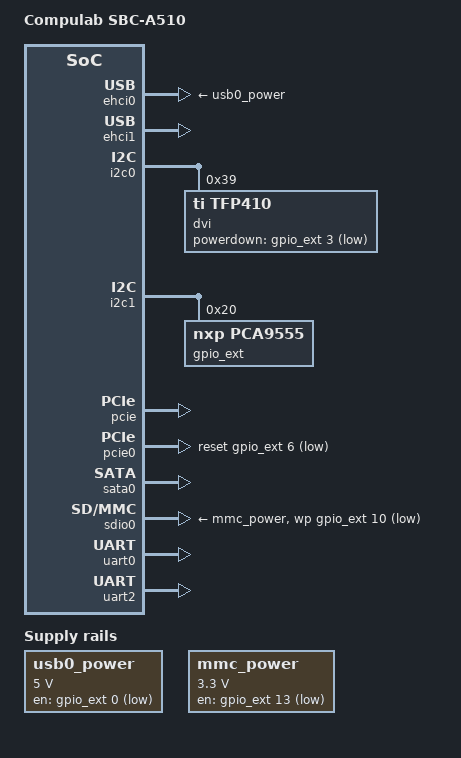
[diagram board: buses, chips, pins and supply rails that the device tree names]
/dts-v1/;
#include "dove-cm-a510.dtsi"
/ {
	model = "Compulab SBC-A510";
	compatible = "compulab,sbc-a510", "compulab,cm-a510", "marvell,dove";
	chosen {
		stdout-path = &uart0;
	};
	usb0_power: regulator-2 {
		compatible = "regulator-fixed";
		regulator-name = "USB Power";
		regulator-min-microvolt = <5000000>;
		regulator-max-microvolt = <5000000>;
		gpio = <&gpio_ext 0 GPIO_ACTIVE_HIGH>;
	};
	mmc_power: regulator-3 {
		compatible = "regulator-fixed";
		regulator-name = "MMC Power";
		regulator-min-microvolt = <3300000>;
		regulator-max-microvolt = <3300000>;
		gpio = <&gpio_ext 13 GPIO_ACTIVE_HIGH>;
	};
};
&mdio { status = "disabled"; };
&eth { status = "disabled"; };
&ethphy { status = "disabled"; };
&ehci0 {
	status = "okay";
	vbus-supply = <&usb0_power>;
};
&ehci1 { status = "okay"; };
&i2c {
	pinctrl-0 = <&pmx_i2c1>;
	pinctrl-names = "default";
};
&i2c0 {
	dvi: video@39 {
		compatible = "ti,tfp410";
		reg = <0x39>;
		powerdown-gpio = <&gpio_ext 3 GPIO_ACTIVE_LOW>;
	};
};
&i2c1 {
	status = "okay";
	gpio_ext: gpio@20 {
		compatible = "nxp,pca9555";
		reg = <0x20>;
		gpio-controller;
		#gpio-cells = <2>;
	};
};
&pcie { status = "okay"; };
&pcie0 {
	status = "okay";
	pinctrl-0 = <&pmx_pcie0_clkreq>;
	pinctrl-names = "default";
	reset-gpios = <&gpio_ext 6 GPIO_ACTIVE_LOW>;
};
&pcie1 { status = "disabled"; };
&sata0 { status = "okay"; };
&sdio0 {
	vmmc-supply = <&mmc_power>;
	wp-gpios = <&gpio_ext 10 GPIO_ACTIVE_LOW>;
	status = "okay";
};
&uart0 { status = "okay"; };
&uart2 { status = "okay"; };
